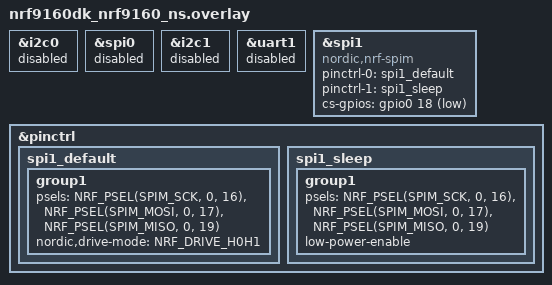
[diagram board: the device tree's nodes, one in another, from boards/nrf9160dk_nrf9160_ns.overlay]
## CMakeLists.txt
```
#
# Copyright (c) 2024 Evercars
#

cmake_minimum_required(VERSION 3.20.0)
find_package(Zephyr REQUIRED HINTS $ENV{ZEPHYR_BASE})
project(spi_test)
zephyr_compile_definitions(PROJECT_NAME=${PROJECT_NAME})

# NORDIC SDK APP START
target_sources(app PRIVATE src/main.c)

add_subdirectory(src/events)
add_subdirectory(src/modules)

# NORDIC SDK APP END
```

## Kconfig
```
#
# Copyright (c) 2024 Ever Cars
#

menu "SPI Test Configuration"

config TERMINAL_UI
    bool "Enable Terminal UI"
    default n
    help
        Enable this option to enable terminal UI. This will enable a minimal UI through UART.

endmenu

menu "Zephyr Kernel"
source "Kconfig.zephyr"
endmenu
```

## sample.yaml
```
sample:
  description: Application to test SPI interface of NRF9160
  name: SPI Test
tests:
  app.spi-test:
    sysbuild: true
    build_only: true
    integration_platforms:
      - nrf9160dk/nrf9160/ns
    tags: ci_build sysbuild
```

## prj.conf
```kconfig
#
# Copyright (c) 2024 Evercars
#

# Enable logging
CONFIG_LOG=y
CONFIG_CBPRINTF_FP_SUPPORT=y
CONFIG_RESET_ON_FATAL_ERROR=n

# UART Configuration
CONFIG_SERIAL=y
CONFIG_UART_ASYNC_API=y

# Configure Peripharals
CONFIG_GPIO=y
CONFIG_SPI=y

# Enabling assert
CONFIG_ASSERT=y

# Configuration required by Application Event Manager
CONFIG_APP_EVENT_MANAGER=y
CONFIG_HEAP_MEM_POOL_SIZE=2048
CONFIG_REBOOT=y
```

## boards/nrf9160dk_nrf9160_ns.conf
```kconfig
#UART1 is used for TF-M logging should be disabled
CONFIG_TFM_SECURE_UART=n
CONFIG_TFM_LOG_LEVEL_SILENCE=y
CONFIG_LED_GPIO=y
```

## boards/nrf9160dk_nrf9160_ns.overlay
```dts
/* From Nordic Academy */
&i2c0 {	status = "disabled";};
&spi0 {	status = "disabled";};
&i2c1 {	status = "disabled";};
&uart1 { status = "disabled";};
	
spi_master: &spi1 {
    compatible = "nordic,nrf-spim";
	status = "okay";
	pinctrl-0 = <&spi1_default>;
	pinctrl-1 = <&spi1_sleep>;
	pinctrl-names = "default", "sleep";
	cs-gpios = <&gpio0 18 GPIO_ACTIVE_LOW>;
};

/* SPI pin configuration */
&pinctrl {
	spi1_default: spi1_default {
		group1 {
				psels = <NRF_PSEL(SPIM_SCK, 0, 16)>,
						<NRF_PSEL(SPIM_MOSI, 0, 17)>,
						<NRF_PSEL(SPIM_MISO, 0, 19)>;
				nordic,drive-mode = <NRF_DRIVE_H0H1>;
		};
	};

	spi1_sleep: spi1_sleep {
		group1 {
				psels = <NRF_PSEL(SPIM_SCK, 0, 16)>,
						<NRF_PSEL(SPIM_MOSI, 0, 17)>,
						<NRF_PSEL(SPIM_MISO, 0, 19)>;
				low-power-enable;
		};
	};
};
```

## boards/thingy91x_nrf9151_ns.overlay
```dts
/* From Nordic Academy */
&i2c0 {	status = "disabled";};
&spi0 {	status = "disabled";};
&i2c1 {	status = "disabled";};
&uart1 { status = "disabled";};
    
spi_master: &spi1 {
    compatible = "nordic,nrf-spim";
    status = "okay";
    pinctrl-0 = <&spi1_default>;
    pinctrl-1 = <&spi1_sleep>;
    pinctrl-names = "default", "sleep";
    cs-gpios = <&gpio0 11 GPIO_ACTIVE_LOW>;
};

/* SPI pin configuration */
&pinctrl {
    spi1_default: spi1_default {
        group1 {
                psels = <NRF_PSEL(SPIM_SCK, 0, 12)>,
                        <NRF_PSEL(SPIM_MOSI, 0, 10)>,
                        <NRF_PSEL(SPIM_MISO, 0, 9)>;
                nordic,drive-mode = <NRF_DRIVE_H0H1>;
        };
    };

    spi1_sleep: spi1_sleep {
        group1 {
                psels = <NRF_PSEL(SPIM_SCK, 0, 12)>,
                        <NRF_PSEL(SPIM_MOSI, 0, 10)>,
                        <NRF_PSEL(SPIM_MISO, 0, 9)>;
                low-power-enable;
        };
    };
};
```

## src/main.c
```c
/*
 * Copyright (c) 2024 Evercars
 */

#include <zephyr/kernel.h>
#include <zephyr/logging/log.h>
#include <zephyr/sys/reboot.h>

/* Include the header files for SPI, GPIO and devicetree */
#include <zephyr/device.h>
#include <zephyr/devicetree.h>
#include <zephyr/drivers/gpio.h>
#include <zephyr/drivers/spi.h>

/* CAF Application Event Manager Framework */
#include <app_event_manager.h>

#define MODULE main
LOG_MODULE_REGISTER(MODULE, LOG_LEVEL_INF);

void print_banner(void)
{
    LOG_INF("**********************");
    LOG_INF("        RICHIE");
    LOG_INF("**********************");
}

int main(void)
{
    print_banner();

    if (app_event_manager_init()) {
        /* Without the Application Event Manager, the application will not work
		 * as intended. A reboot is required in an attempt to recover.
		 */
		LOG_ERR("Application Event Manager could not be initialized, rebooting...");
		k_sleep(K_SECONDS(5));
		sys_reboot(SYS_REBOOT_COLD);
    }

    LOG_INF("AEM Initialization complete!");
    
    return 0;
}
```
